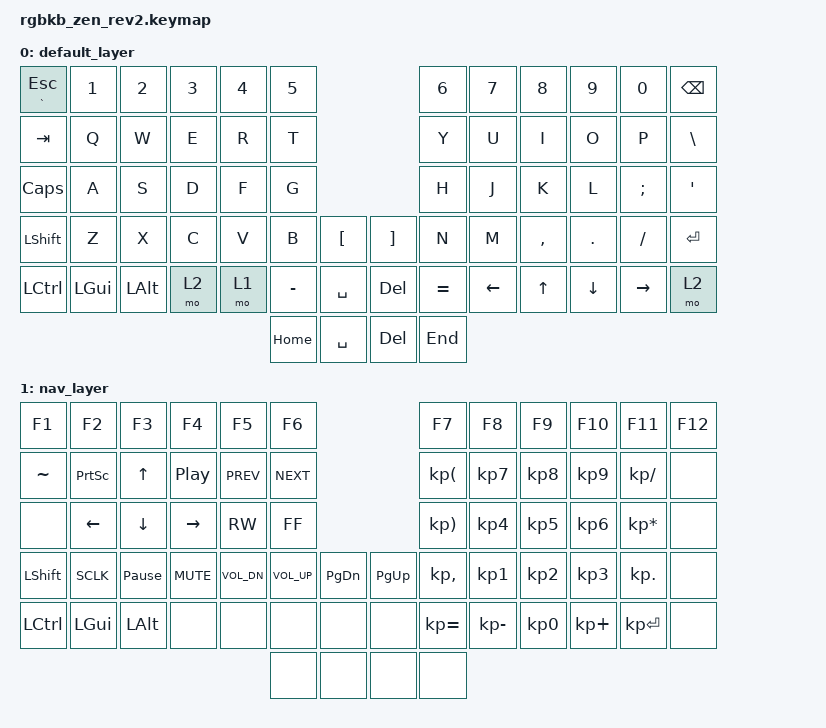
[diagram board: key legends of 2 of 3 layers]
/*
 * Copyright (c) 2020 The ZMK Contributors
 *
 * SPDX-License-Identifier: MIT
 */

#include <behaviors.dtsi>
#include <dt-bindings/zmk/keys.h>
#include <dt-bindings/zmk/bt.h>
#include <dt-bindings/zmk/rgb.h>
#include <dt-bindings/zmk/outputs.h>
#include <dt-bindings/zmk/ext_power.h>

/ {  
        keymap {
                compatible = "zmk,keymap";

                default_layer {
// Qwerty
// ,-----------------------------------------.              .-----------------------------------------.
// |`~ ESC|  1 ! |  2 @ |  3 # |  4 $ |  5 % |              |  6 ^ |  7 & |  8 * |  9 ( |  0 ) | BSPC |
// |------+------+------+------+------+------|              |------+------+------+------+------+------|
// | Tab  |   Q  |   W  |   E  |   R  |   T  |              |   Y  |   U  |   I  |   O  |   P  |  \ | |
// |------+------+------+------+------+------|              |------+------+------+------+------+------|
// | CAPS |   A  |   S  |   D  |   F  |   G  |              |   H  |   J  |   K  |   L  |  ; : |  ' " |
// |------+------+------+------+------+------+------..------+------+------+------+------+------+------|
// | Shift|   Z  |   X  |   C  |   V  |   B  |   [{ ||  }]  |   N  |   M  |  , < |  . > |  / ? |Enter |
// |------+------+------+------+------+------+------||------+------+------+------+------+------+------|
// | Ctrl | GUI  | Alt  |MOVE 2|MOVE 1|  - _ | SPACE||  DEL |  = + |   ←  |   ↑  |   ↓  |   →  |MOVE 2|
// `----------------------------------+-------------''------------------------------------------------'
//                                    | HOME | SPACE||  DEL |  END |
//                                    '-------------''-------------'
//
                        bindings = <
   &mt GRAVE ESC &kp N1   &kp N2   &kp N3 &kp N4 &kp N5                        &kp N6    &kp N7   &kp N8    &kp N9   &kp N0    &kp BSPC
   &kp TAB       &kp Q    &kp W    &kp E  &kp R  &kp T                         &kp Y     &kp U    &kp I     &kp O    &kp P     &kp BSLH
   &kp CLCK      &kp A    &kp S    &kp D  &kp F  &kp G                         &kp H     &kp J    &kp K     &kp L    &kp SEMI  &kp SQT
   &kp LSHFT     &kp Z    &kp X    &kp C  &kp V  &kp B     &kp LBKT  &kp RBKT  &kp N     &kp M    &kp COMMA &kp DOT  &kp FSLH  &kp RET
   &kp LCTRL     &kp LGUI &kp LALT &mo 2  &mo 1  &kp MINUS &kp SPACE &kp DEL   &kp EQUAL &kp LEFT &kp UP    &kp DOWN &kp RIGHT &mo 2
                                                 &kp HOME  &kp SPACE &kp DEL   &kp END
                        >;
                };

                nav_layer {
// Qwerty
// ,----------------------------------------------.              .-----------------------------------------.
// | F1   |   F2  |   F3  |  F4   |   F5  |   F6  |              |   F7 |   F8 |   F9 |  F10 |  F11 |  F12 |
// |------+-------+-------+-------+-------+-------|              |------+------+------+------+------+------|
// |  `   | PSCRN |   UP  | PLAY  |  PREV |  NEXT |              |  (   |   7  |   8  |   9  |   /  |      |
// |------+-------+-------+-------+-------+-------|              |------+------+------+------+------+------|
// |      |  LEFT |  DOWN | RIGHT |  RW   |  FF   |              |  )   |   4  |   5  |   6  |   *  |      |
// |------+-------+-------+-------+-------+-------+------..------+------+------+------+------+------+------|
// | Shift|  SCLK | PAUSE | MUTE  | VOLDN | VOLUP | PGDN || PGUP |  ,   |   1  |   2  |   3  |   .  |      |
// |------+-------+-------+-------+-------+-------+------||------+------+------+------+------+------+------|
// | Ctrl |  GUI  |  Alt  |       |       |       |      ||      |  =   |   -  |   0  |   +  |  RET |      |
// `--------------------------------------+--------------''------------------------------------------------'
//                                        |       |      ||      |      |
//                                        '--------------''-------------'
//
                        bindings = <
   &kp F1    &kp F2      &kp F3           &kp F4       &kp F5       &kp F6                           &kp F7       &kp F8       &kp F9     &kp F10     &kp F11         &kp F12
   &kp TILDE &kp PSCRN   &kp UP           &kp C_PP     &kp C_PREV   &kp C_NEXT                       &kp KP_LPAR  &kp KP_N7    &kp KP_N8  &kp KP_N9   &kp KP_DIVIDE   &none 
   &none     &kp LEFT    &kp DOWN         &kp RIGHT    &kp C_RW     &kp C_FF                         &kp KP_RPAR  &kp KP_N4    &kp KP_N5  &kp KP_N6   &kp KP_MULTIPLY &none 
   &kp LSHFT &kp SCLK    &kp PAUSE_BREAK  &kp C_MUTE   &kp C_VOL_DN &kp C_VOL_UP &kp PG_DN &kp PG_UP &kp KP_COMMA &kp KP_N1    &kp KP_N2  &kp KP_N3   &kp KP_DOT      &none 
   &kp LCTRL &kp LGUI    &kp LALT         &none        &none        &none        &none     &none     &kp KP_EQUAL &kp KP_MINUS &kp KP_N0  &kp KP_PLUS &kp KP_ENTER    &none    
                                                                    &none        &none     &none     &none
                        >;
                };

                special_layer {
// Qwerty
// ,----------------------------------------------.              .-----------------------------------------.
// |      |       |       |       |       |       |              |      |      |      |      |      |      |
// |------+-------+-------+-------+-------+-------|              |------+------+------+------+------+------|
// |      |RGB_SAI|RGB_SAD|RGB_BRI|RGB_BRD|RGB_EFF|              |      |      |      |      |      |      |
// |------+-------+-------+-------+-------+-------|              |------+------+------+------+------+------|
// | RESET|RGB_HUI|RGB_HUD|RGB_SPI|RGB_SPD|RGB_EFR|              |      |      |      |      |      |RESET |
// |------+-------+-------+-------+-------+-------+------..------+------+------+------+------+------+------|
// | Shift|BT_CLR |BT_NXT |BT_PRV |OUT_TOG|RGB_TOG|      ||      |      |      |      |      |      |      |
// |------+-------+-------+-------+-------+-------+------||------+------+------+------+------+------+------|
// | Ctrl |  GUI  |  Alt  |       |       |       |      ||      |      |      |      |      |      |      |
// `--------------------------------------+--------------''------------------------------------------------'
//                                        |       |      ||      |      |
//                                        '--------------''-------------'
//
                        bindings = <
   &none      &ext_power EP_ON &ext_power EP_OFF &ext_power EP_TOG &none           &none                                &none    &none     &none      &none      &none        &none
   &none           &rgb_ug RGB_SAI &rgb_ug RGB_SAD &rgb_ug RGB_BRI &rgb_ug RGB_BRD &rgb_ug RGB_EFF                      &none    &none     &none      &none      &none        &none 
   &reset          &rgb_ug RGB_HUI &rgb_ug RGB_HUD &rgb_ug RGB_SPI &rgb_ug RGB_SPD &rgb_ug RGB_EFR                      &none    &none     &none      &none      &none        &reset 
   &kp LSHFT       &bt BT_CLR      &bt BT_NXT      &bt BT_PRV      &out OUT_TOG    &rgb_ug RGB_TOG &none       &none    &none    &none     &none      &none      &none        &none  
   &kp LCTRL       &kp LGUI        &kp LALT        &none           &none           &none           &none       &none    &none    &none     &none      &none      &none    
                                                                                   &none           &none       &none    &none
                        >;
                };
        };
};
